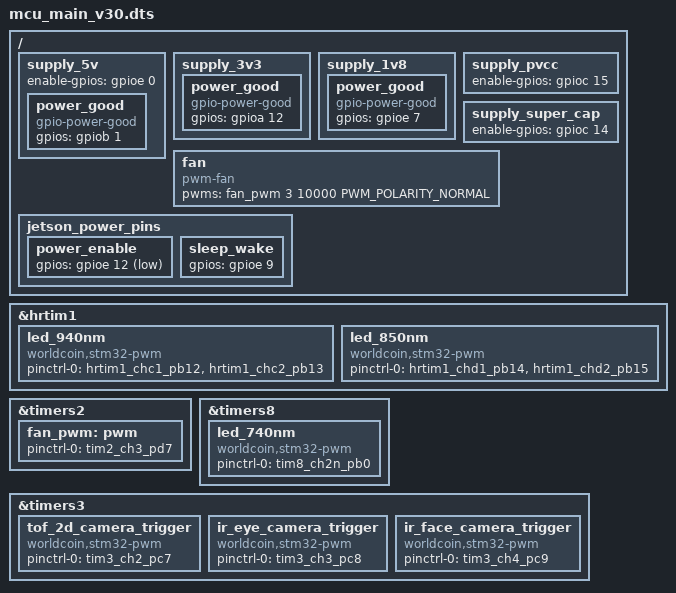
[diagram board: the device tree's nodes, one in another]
/dts-v1/;

#include "mcu_main_common.dts"

/ {
    supply_5v {
        enable-gpios = <&gpioe 0 GPIO_ACTIVE_HIGH>;
        power_good {
            compatible = "gpio-power-good";
            gpios = <&gpiob 1 GPIO_PULL_UP>;
        };
    };

    supply_3v3 {
        power_good {
            compatible = "gpio-power-good";
            gpios = <&gpioa 12 GPIO_PULL_UP>;
        };
    };

    supply_1v8 {
        power_good {
            compatible = "gpio-power-good";
            gpios = <&gpioe 7 GPIO_PULL_UP>;
        };
    };

    supply_pvcc {
        enable-gpios = <&gpioc 15 GPIO_ACTIVE_HIGH>;
    };

    supply_super_cap {
        enable-gpios = <&gpioc 14 GPIO_ACTIVE_HIGH>;
    };

    fan {
        compatible = "pwm-fan";
        pwms = <&fan_pwm 3 10000 PWM_POLARITY_NORMAL>;

        // No tachometer reading, only a 2-wire fan
    };

    jetson_power_pins {
        power_enable {
            gpios = <&gpioe 12 (GPIO_ACTIVE_LOW | GPIO_OPEN_DRAIN)>;
        };

        sleep_wake {
            gpios = <&gpioe 9 GPIO_ACTIVE_HIGH>;
        };
    };
};

&hrtim1 {
    status = "okay";
    led_940nm: led_940nm {
        compatible = "worldcoin,stm32-pwm";
        pinctrl-0 = <&hrtim1_chc1_pb12 &hrtim1_chc2_pb13>;
        pinctrl-names = "default";
    };

    led_850nm: led_850nm {
        compatible = "worldcoin,stm32-pwm";
        pinctrl-0 = <&hrtim1_chd1_pb14 &hrtim1_chd2_pb15>;
        pinctrl-names = "default";
    };
};

&timers2 {
    status = "okay";

    fan_pwm: pwm {
        status = "okay";
        pinctrl-0 = <&tim2_ch3_pd7>;
        pinctrl-names = "default";
    };
};

&timers8 {
    status = "okay";
    led_740nm: led_740nm {
        compatible = "worldcoin,stm32-pwm";
        pinctrl-0 = <&tim8_ch2n_pb0>;
        pinctrl-names = "default";
    };
};

&timers3 {
    status = "okay";
    // AKA CAM3
    tof_2d_camera_trigger: tof_2d_camera_trigger {
        compatible = "worldcoin,stm32-pwm";
        pinctrl-0 = <&tim3_ch2_pc7>;
        pinctrl-names = "default";
    };

    // AKA CAM0
    ir_eye_camera_trigger: ir_eye_camera_trigger {
        compatible = "worldcoin,stm32-pwm";
        pinctrl-0 = <&tim3_ch3_pc8>;
        pinctrl-names = "default";
    };

    // AKA CAM2
    ir_face_camera_trigger: ir_face_camera_trigger {
        compatible = "worldcoin,stm32-pwm";
        pinctrl-0 = <&tim3_ch4_pc9>;
        pinctrl-names = "default";
    };
};
